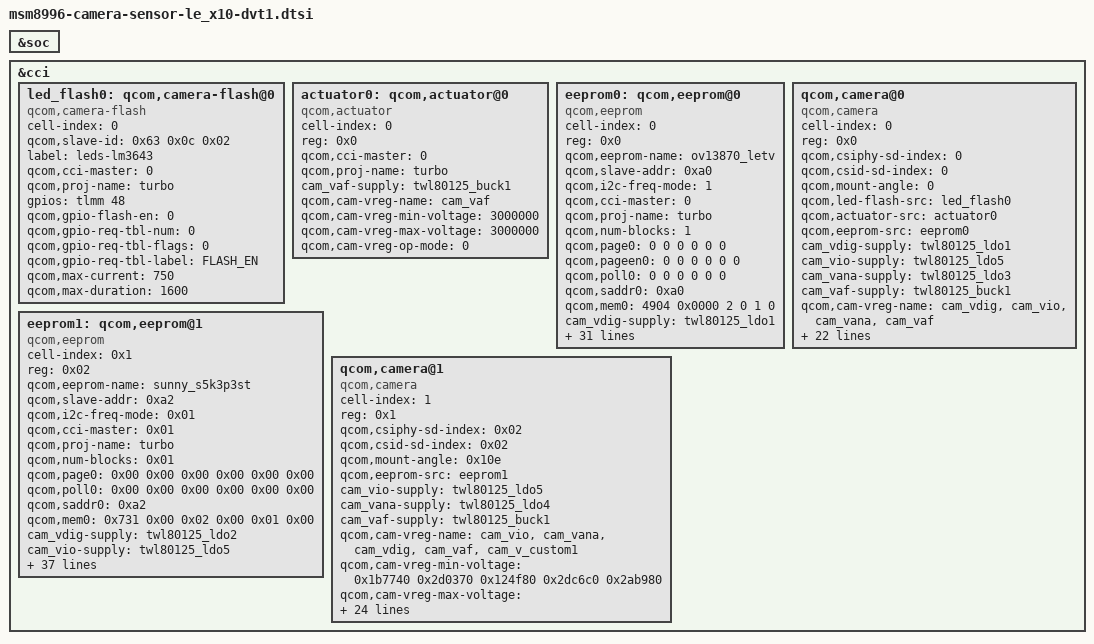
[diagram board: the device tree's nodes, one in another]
/*
 * Copyright (c) 2015 The Linux Foundation. All rights reserved.
 *
 * This program is free software; you can redistribute it and/or modify
 * it under the terms of the GNU General Public License version 2 and
 * only version 2 as published by the Free Software Foundation.
 *
 * This program is distributed in the hope that it will be useful,
 * but WITHOUT ANY WARRANTY; without even the implied warranty of
 * MERCHANTABILITY or FITNESS FOR A PARTICULAR PURPOSE.  See the
 * GNU General Public License for more details.
 */

&soc {
};

&cci {
	led_flash0: qcom,camera-flash@0 {
		cell-index = <0>;
		qcom,slave-id = <0x63 0x0c 0x02>;
		compatible = "qcom,camera-flash";
		label = "leds-lm3643";
		qcom,cci-master = <0>;
		qcom,proj-name = "turbo";
		gpios = <&tlmm 48 0>;
		qcom,gpio-flash-en = <0>;
		qcom,gpio-req-tbl-num = <0>;
		qcom,gpio-req-tbl-flags = <0>;
		qcom,gpio-req-tbl-label = "FLASH_EN";
		qcom,max-current = <750>;
		qcom,max-duration = <1600>;
	};

	actuator0: qcom,actuator@0 {
        cell-index = <0>;
        reg = <0x0>;
        compatible = "qcom,actuator";
        qcom,cci-master = <0>;
        qcom,proj-name = "turbo";
        cam_vaf-supply = <&twl80125_buck1>;
        qcom,cam-vreg-name = "cam_vaf";
        qcom,cam-vreg-min-voltage = <3000000>;
        qcom,cam-vreg-max-voltage = <3000000>;
        qcom,cam-vreg-op-mode = <0>;
    };

    eeprom0: qcom,eeprom@0 {
		cell-index = <0>;
		reg = <0x0>;
		qcom,eeprom-name = "ov13870_letv";
		compatible = "qcom,eeprom";
		qcom,slave-addr = <0xa0>;
		qcom,i2c-freq-mode = <1>;
		qcom,cci-master = <0>;
		qcom,proj-name = "turbo";
		qcom,num-blocks = <1>;

		qcom,page0 = <0 0 0 0 0 0>;
		qcom,pageen0 = <0 0 0 0 0 0>;
		qcom,poll0 = <0 0 0 0 0 0>;
		qcom,saddr0  = <0xa0>;
		qcom,mem0 = <4904 0x0000 2 0 1 0>;

		cam_vdig-supply = <&twl80125_ldo1>;
		cam_vio-supply = <&twl80125_ldo5>;
		cam_vana-supply = <&twl80125_ldo3>;
		cam_vaf-supply = <&twl80125_buck1>;
		qcom,cam-vreg-name = "cam_vdig", "cam_vio", "cam_vana","cam_vaf";
		qcom,cam-vreg-min-voltage = <1200000 1800000 2800000 3000000>;
		qcom,cam-vreg-max-voltage = <1200000 1800000 2800000 3000000>;
		qcom,cam-vreg-op-mode = <0 0 0 0>;
		qcom,gpio-no-mux = <0>;
		pinctrl-names = "cam_default", "cam_suspend";
		pinctrl-0 = <&cam_sensor_mclk1_active &cam_sensor_rear_active>;
		pinctrl-1 = <&cam_sensor_mclk1_suspend &cam_sensor_rear_suspend>;
		
		gpios = <&tlmm 13 0>,
			    <&tlmm 30 0>;
		
		qcom,gpio-standby = <1>;
		qcom,gpio-req-tbl-num = <0 1>;
		qcom,gpio-req-tbl-flags = <1 0>;
		qcom,gpio-req-tbl-label = "CAMIF_MCLK0",
					              "CAM_STANDBY0";

		qcom,cam-power-seq-type = "sensor_vreg", "sensor_vreg", "sensor_vreg","sensor_vreg",
			"sensor_gpio" , "sensor_clk";
		qcom,cam-power-seq-val = "cam_vdig", "cam_vana", "cam_vio","cam_vaf",
			 "sensor_gpio_standby","sensor_cam_mclk";
		qcom,cam-power-seq-cfg-val = <1 1 1 1 1 24000000>;
		qcom,cam-power-seq-delay = <1 1 30 30 30 5>;

		clocks = <&clock_mmss clk_mclk1_clk_src>,
						<&clock_mmss clk_camss_mclk1_clk>;
				clock-names = "cam_src_clk", "cam_clk";
	};

	qcom,camera@0 {
		cell-index = <0>;
		compatible = "qcom,camera";
		reg = <0x0>;
		qcom,csiphy-sd-index = <0>;
		qcom,csid-sd-index = <0>;
		qcom,mount-angle = <0>;
		qcom,led-flash-src = <&led_flash0>;
		qcom,actuator-src = <&actuator0>;
		//qcom,ois-src = <&ois0>;
		qcom,eeprom-src = <&eeprom0>;
		cam_vdig-supply = <&twl80125_ldo1>;
		cam_vio-supply = <&twl80125_ldo5>;
		cam_vana-supply = <&twl80125_ldo3>;
		cam_vaf-supply = <&twl80125_buck1>;
		qcom,cam-vreg-name = "cam_vdig", "cam_vio", "cam_vana","cam_vaf";
		qcom,cam-vreg-min-voltage = <1200000 1800000 2800000 3000000>;
		qcom,cam-vreg-max-voltage = <1200000 1800000 2800000 3000000>;
		qcom,cam-vreg-op-mode = <0 0 0 0>;
		qcom,gpio-no-mux = <0>;
		pinctrl-names = "cam_default", "cam_suspend";
		pinctrl-0 = <&cam_sensor_mclk1_active &cam_sensor_rear_active>;
		pinctrl-1 = <&cam_sensor_mclk1_suspend &cam_sensor_rear_suspend>;
		
		gpios = <&tlmm 13 0>,
		    <&tlmm 30 0>;
		
		qcom,gpio-standby = <1>;
		qcom,gpio-req-tbl-num = <0 1>;
		qcom,gpio-req-tbl-flags = <1 0>;
		qcom,gpio-req-tbl-label = "CAMIF_MCLK0",
					  "CAM_STANDBY0";
		qcom,sensor-position = <0>;
		qcom,sensor-mode = <0>;
		qcom,cci-master = <0>;
		qcom,proj-name = "turbo";
		status = "ok";
		clocks = <&clock_mmss clk_mclk1_clk_src>,
				<&clock_mmss clk_camss_mclk1_clk>;
		clock-names = "cam_src_clk", "cam_clk";
	};

	eeprom1: qcom,eeprom@1 {
		cell-index = < 0x1 >;
		reg = < 0x02 >;
		qcom,eeprom-name = "sunny_s5k3p3st";
		compatible = "qcom,eeprom";
		qcom,slave-addr = < 0xa2 >;
		qcom,i2c-freq-mode = < 0x01 >;
		qcom,cci-master = < 0x01 >;
		qcom,proj-name = "turbo";
		qcom,num-blocks = < 0x01 >;

		qcom,page0 = < 0x00 0x00 0x00 0x00 0x00 0x00 >;
		qcom,poll0 = < 0x00 0x00 0x00 0x00 0x00 0x00 >;
		qcom,saddr0 = < 0xa2 >;
		qcom,mem0 = < 0x731 0x00 0x02 0x00 0x01 0x00 >;

		cam_vdig-supply = <&twl80125_ldo2>;
		cam_vio-supply = <&twl80125_ldo5>;
		cam_vana-supply = <&twl80125_ldo4>;
		cam_vaf-supply = <&twl80125_buck2>;

		cam_v_custom1-supply = <&twl80125_ldo2>;
		cam_v_custom2-supply = <&twl80125_ldo4>;

		qcom,cam-vreg-name = "cam_vio,cam_vana,cam_vdig,cam_vaf,cam_v_custom1";
		qcom,cam-vreg-type = < 0x00 0x00 0x00 0x00 0x00 0x00 >;
		qcom,cam-vreg-min-voltage = < 0x1b7740 0x2d0370 0x124f80 0x2dc6c0 0x2ab980 >;
		qcom,cam-vreg-max-voltage = < 0x1b7740 0x2d0370 0x124f80 0x2dc6c0 0x2ab980 >;
		qcom,cam-vreg-op-mode = < 0x13880 0x13880 0x00 0x13880 0x13880 >;
		qcom,gpio-no-mux = < 0x00 >;
		pinctrl-names = "cam_default,cam_suspend";

		pinctrl-0 = <&cam_sensor_mclk3_active &cam_sensor_rear_active>;
		pinctrl-1 = <&cam_sensor_mclk3_suspend &cam_sensor_rear_suspend>;

		gpios = <&tlmm 16 0>,
			<&tlmm 10 0>,
			<&tlmm 84 0>;

		qcom,gpio-reset = < 0x01 >;
		qcom,gpio-req-tbl-num = < 0x00 0x01 0x02 >;
		qcom,gpio-req-tbl-flags = < 0x01 0x00 0x00 >;
		qcom,gpio-req-tbl-label = "CAMIF_MCLK2,CAM_RESET2,MONO_CAM_STANDBY";
		qcom,cam-power-seq-type = "sensor_vreg,sensor_vreg,sensor_vreg,sensor_vreg,sensor_vreg,sensor_gpio,sensor_clk";
		qcom,cam-power-seq-val = "cam_vdig,cam_vana,cam_vio,cam_vaf,cam_v_custom1,sensor_gpio_standby,sensor_cam_mclk";
		qcom,cam-power-seq-cfg-val = < 0x01 0x01 0x01 0x01 0x01 0x01 0x16e3600 >;
		qcom,cam-power-seq-delay = < 0x01 0x01 0x1e 0x1e 0x1e 0x1e 0x05 >;
		status = "ok";

		clocks = <&clock_mmss clk_mclk3_clk_src>,
			 <&clock_mmss clk_camss_mclk3_clk>;
		clock-names = "cam_src_clk,cam_clk";
		qcom,gpio-custom1 = < 0x02 >;
		qcom,clock-rates = < 0x16e3600 0x00 >;
	};

	qcom,camera@1 {
		cell-index = <1>;
		compatible = "qcom,camera";
		reg = <0x1>;
		qcom,csiphy-sd-index = < 0x02 >;
		qcom,csid-sd-index = < 0x02 >;
		qcom,mount-angle = < 0x10e >;

		qcom,eeprom-src = < &eeprom1 >;
		cam_vio-supply = <&twl80125_ldo5>;
		cam_vana-supply = <&twl80125_ldo4>;
		cam_vaf-supply = <&twl80125_buck1>;

		qcom,cam-vreg-name = "cam_vio", "cam_vana", "cam_vdig", "cam_vaf", "cam_v_custom1";
		qcom,cam-vreg-min-voltage = < 0x1b7740 0x2d0370 0x124f80 0x2dc6c0 0x2ab980 >;
		qcom,cam-vreg-max-voltage = < 0x1b7740 0x2d0370 0x124f80 0x2dc6c0 0x2ab980 >;
		qcom,cam-vreg-op-mode = < 0x13880 0x13880 0x00 0x13880 0x13880 >;
		qcom,gpio-no-mux = < 0x00 >;
		pinctrl-names = "cam_default", "cam_suspend";

		pinctrl-0 = <&cam_sensor_mclk3_active &cam_sensor_rear_active>;
		pinctrl-1 = <&cam_sensor_mclk3_suspend &cam_sensor_rear_suspend>;
		
		gpios = <&tlmm 16 0>,
			<&tlmm 10 0>,
			<&tlmm 84 0>;
		
		qcom,gpio-reset = < 0x01 >;
		qcom,gpio-req-tbl-num = < 0x00 0x01 0x02 >;
		qcom,gpio-req-tbl-flags = < 0x01 0x00 0x00 >;
		qcom,gpio-req-tbl-label = "CAMIF_MCLK2", "CAM_RESET2", "MONO_CAM_STANDBY";
		qcom,sensor-position = < 0x01 >;
		qcom,sensor-mode = < 0x00 >;
		qcom,cci-master = < 0x01 >;
		qcom,proj-name = "turbo";
		status = "ok";

		clocks = <&clock_mmss clk_mclk3_clk_src>,
			 <&clock_mmss clk_camss_mclk3_clk>;
		clock-names = "cam_src_clk", "cam_clk";
		cam_vdig-supply = < 0x1de >;
		cam_v_custom1-supply = < 0x1e0 >;
		qcom,gpio-custom1 = < 0x02 >;
		qcom,clock-rates = < 0x16e3600 0x00 >;
	};
};
